# VTNF register map
Vendor: Texas Instruments
Peripheral module from a debugger description file (folder DRA74xP_75xP_76xP_77xP).
Registers are 32-bit, read-write, reset 0x0 unless marked. A register's access mark holds for its fields unless they carry their own. Offsets are as the file gives them; lines under a group give offsets from that group; [hi:lo] are bit positions; {n}, {i} and the like mark numbered series; 'fields as' and 'values as' point back to an identical list; <NAME> marks a mode.

## VTNF
0x00 VTNF_REVISION ro reset not defined — IP Revision Identifier (X.Y.R) Used by software to track features, bugs, and compatibility
  [31:0] REVISION — IP Revision
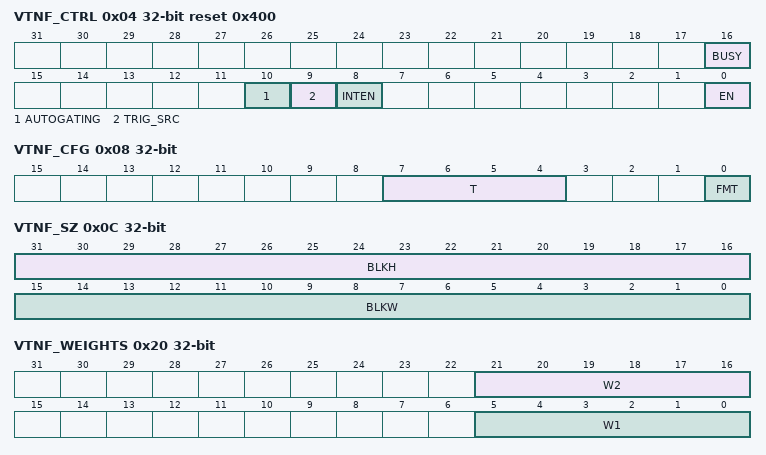
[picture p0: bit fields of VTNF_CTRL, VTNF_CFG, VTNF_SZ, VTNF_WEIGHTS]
0x04 VTNF_CTRL access per field reset 0x400 — Control
  [16] BUSY ro — Idle/busy status (read-only) 0 = idle 1 = busy
  [10] AUTOGATING rw — Internal clock gating on OCP clock and functional clock 0 = clocks are free-running 1 = clocks are gated off in subblocks that are not needed for operation
  [9] TRIG_SRC rw — Starting mechanism trigger source 0 = software writing 1 to EN 1 = HW sequencer sending pulse on START signal
  [8] INTEN rw — Interrupt enable. 0 = disable, 1 = enable.
  [0] EN wo — Write 1 when TRIG_SRC=0 to start module operation. Read back 0 always
0x08 VTNF_CFG access per field
  [7:4] T rw — Round-down number of bits for SAD calculation
  [0] FMT rw — Previous frame output and current frame output format. 0 = NV12 1 = YV12
0x0C VTNF_SZ — Configuration
  [31:16] BLKH — Block height, valid range 4..128, multiple of 4.
  [15:0] BLKW — Block width, valid range 32..512, multiple of 32.
0x10 VTNF_CADR access per field — Current frame input byte address
  [15:4] ADDR rw — Address in 128-bit words. Intention is that software write a byte address into the register. Hardware ignores the lowest 4 bits and bits 15..4 specifies the 128 -bit/word memory address.
0x14 VTNF_PADR access per field — Previous frame output byte address
  fields as VTNF_CADR
0x18 VTNF_OADR access per field — Current frame output byte address
  fields as VTNF_CADR
0x1C VTNF_LOFST access per field — Line offset for C, P, O arrays
  [15:4] LOFST rw — Line offset in 128-bit words. Intention is that software write a byte-count line offset into the register. Hardware ignores the lowest 4 bits and bits 15..4 specifies the 128 -bit/word line offset.
0x20 VTNF_WEIGHTS access per field — Weights for SAD calculation
  [21:16] W2 rw — W2 parameter, chroma weight for SAD calculation.
  [5:0] W1 rw — W1 oarameter, luma weight for SAD calculation.
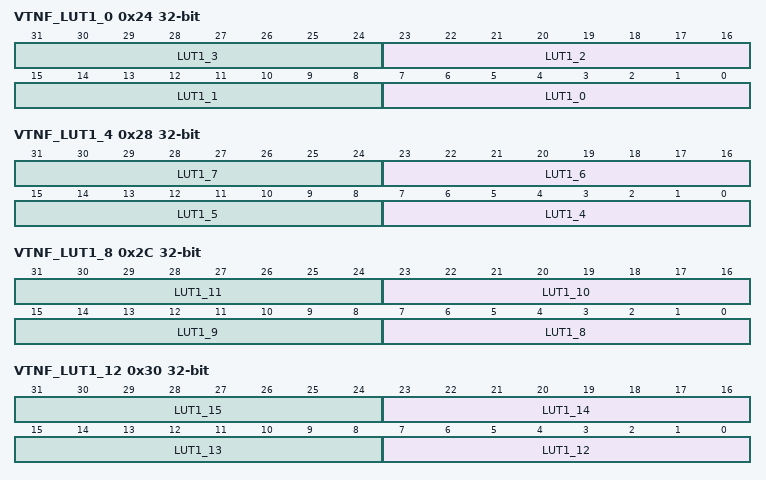
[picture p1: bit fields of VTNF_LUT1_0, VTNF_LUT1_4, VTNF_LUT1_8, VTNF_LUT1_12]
0x24 VTNF_LUT1_0 — Lookup table 1
  [8n+7:8n] LUT1_{n} (n=0..3)
0x28 VTNF_LUT1_4 — Lookup table 1
  [8n-25:8n-32] LUT1_{n} (n=4..7)
0x2C VTNF_LUT1_8 — Lookup table 1
  [8n-57:8n-64] LUT1_{n} (n=8..11)
0x30 VTNF_LUT1_12 — Lookup table 1
  [8n-89:8n-96] LUT1_{n} (n=12..15)
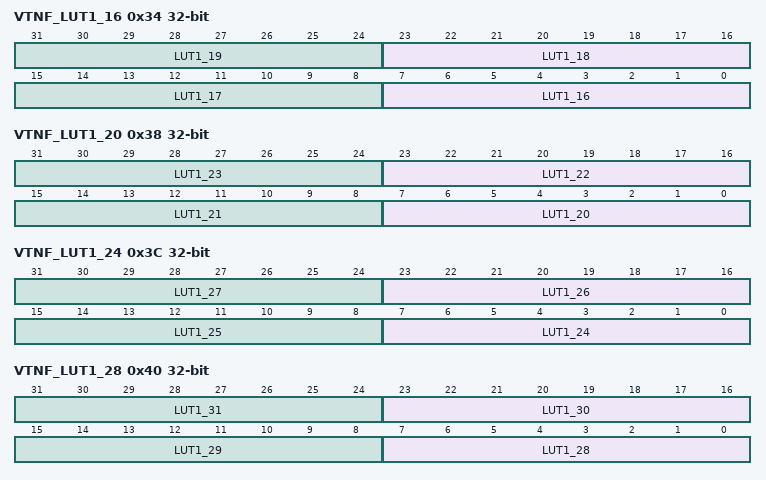
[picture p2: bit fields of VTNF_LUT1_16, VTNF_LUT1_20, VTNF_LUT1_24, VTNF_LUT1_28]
0x34 VTNF_LUT1_16 — Lookup table 1
  [8n-121:8n-128] LUT1_{n} (n=16..19)
0x38 VTNF_LUT1_20 — Lookup table 1
  [8n-153:8n-160] LUT1_{n} (n=20..23)
0x3C VTNF_LUT1_24 — Lookup table 1
  [8n-185:8n-192] LUT1_{n} (n=24..27)
0x40 VTNF_LUT1_28 — Lookup table 1
  [8n-217:8n-224] LUT1_{n} (n=28..31)
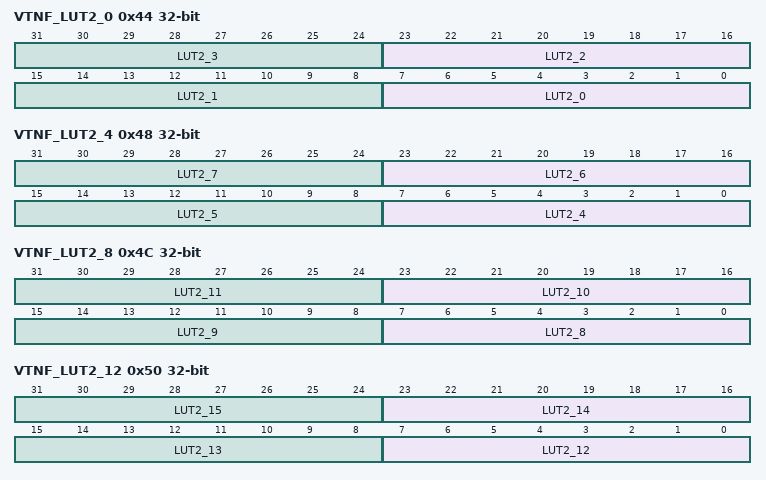
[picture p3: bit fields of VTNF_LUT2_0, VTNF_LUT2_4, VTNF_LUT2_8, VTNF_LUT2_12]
0x44 VTNF_LUT2_0 — Lookup table 1
  [8n+7:8n] LUT2_{n} (n=0..3)
0x48 VTNF_LUT2_4 — Lookup table 1
  [8n-25:8n-32] LUT2_{n} (n=4..7)
0x4C VTNF_LUT2_8 — Lookup table 1
  [8n-57:8n-64] LUT2_{n} (n=8..11)
0x50 VTNF_LUT2_12 — Lookup table 1
  [8n-89:8n-96] LUT2_{n} (n=12..15)
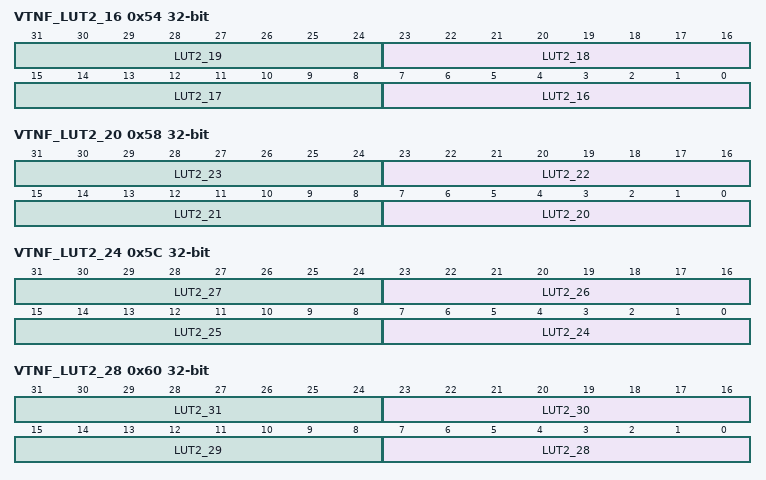
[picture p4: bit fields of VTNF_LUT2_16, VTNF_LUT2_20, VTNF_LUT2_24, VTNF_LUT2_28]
0x54 VTNF_LUT2_16 — Lookup table 1
  [8n-121:8n-128] LUT2_{n} (n=16..19)
0x58 VTNF_LUT2_20 — Lookup table 1
  [8n-153:8n-160] LUT2_{n} (n=20..23)
0x5C VTNF_LUT2_24 — Lookup table 1
  [8n-185:8n-192] LUT2_{n} (n=24..27)
0x60 VTNF_LUT2_28 — Lookup table 1
  [8n-217:8n-224] LUT2_{n} (n=28..31)
